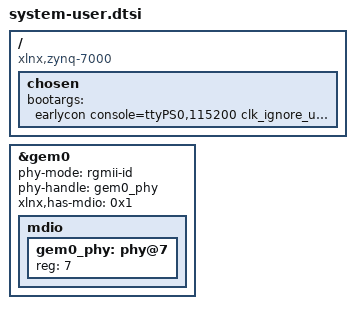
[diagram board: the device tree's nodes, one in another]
// SPDX-License-Identifier: MIT
// Copyright (C) 2025-2026, Opsero Electronic Design Inc.  All rights reserved.

/*
 * SoC-side board fixups for the ZC706 (Zynq-7000), layered on top of the
 * gen-machineconf / lopper-generated cortexa9-linux.dts (which already carries
 * the PS config and the PL axi_pcie Gen2 Root Port from the XSA). Scoped to the
 * Linux domain by device-tree.bbappend.
 *
 * gem0: the board Ethernet port, kept enabled so the image is reachable over
 * the board RJ45 (this design does not otherwise use the PS Ethernet). The
 * generated pcw.dtsi enables gem0 but describes no PHY (no phy-handle, no MDIO
 * child); 2025.x U-Boot data-aborts probing a gem0 in that state, so the PHY
 * is described here. This dtb is also U-Boot's control DT (BOOT.BIN loads it
 * at 0x100000), so U-Boot sees the same description.
 * board RJ45 = PS GEM0 on MIO16-27 (RGMII), MDIO on MIO52/53, Marvell
 * 88E1116R PHY at MDIO address 7, phy-mode rgmii-id (upstream zynq-zc706.dts;
 * PS config of this design's XSA; PHY reset MIO47 comes from the generated DT).
 * No fixed MAC: U-Boot assigns one and passes it on.
 *
 * Kernel command line: the Zynq-7000 EDF boot.scr (meta-xilinx u-boot-xlnx-scr)
 * reads bootargs from /chosen/bootargs and only appends root=. Unlike the
 * zynqMP/Versal flow, the zynq parse-sdt device tree does NOT emit a default
 * bootargs, so /chosen/bootargs is empty -> the kernel boots with no console
 * and no earlycon and appears to hang at "Starting kernel ..." (silent). Set it
 * here. console=ttyPS0 is serial0 (PS UART1 @ 0xe0001000, the board's console);
 * earlycon gives output before the UART driver probes. cma sized for the 1 GB
 * board. root= is appended by the boot.scr (mmcblk0p3 on the EDF wks).
 *
 * Root compatible: the parse-sdt/lopper board merge overwrites the root
 * `compatible` with only the board string (e.g. "xlnx,zc706") and drops the
 * SoC-family "xlnx,zynq-7000" that the base zynq-7000.dtsi sets. The kernel's
 * Zynq machine matches on "xlnx,zynq-7000"; without it the kernel falls back to
 * the generic ARM DT machine ("Hardware name: Generic DT based system"), so
 * zynq_early_slcr_init() never runs, the SLCR base (slcr->data) stays NULL, and
 * the clock-controller PLL setup NULL-derefs -> panic in clk_register_zynq_pll
 * during of_clk_init. Put "xlnx,zynq-7000" back. The board-specific compatible
 * is informational (no driver matches it), so replacing it is harmless.
 */

/ {
	compatible = "xlnx,zynq-7000";

	chosen {
		bootargs = "earlycon console=ttyPS0,115200 clk_ignore_unused cma=512M";
	};
};

&gem0 {
	status = "okay";
	phy-mode = "rgmii-id";
	phy-handle = <&gem0_phy>;
	xlnx,has-mdio = <0x1>;
	mdio {
		#address-cells = <1>;
		#size-cells = <0>;
		gem0_phy: phy@7 {
			device_type = "ethernet-phy";
			reg = <7>;
		};
	};
};
